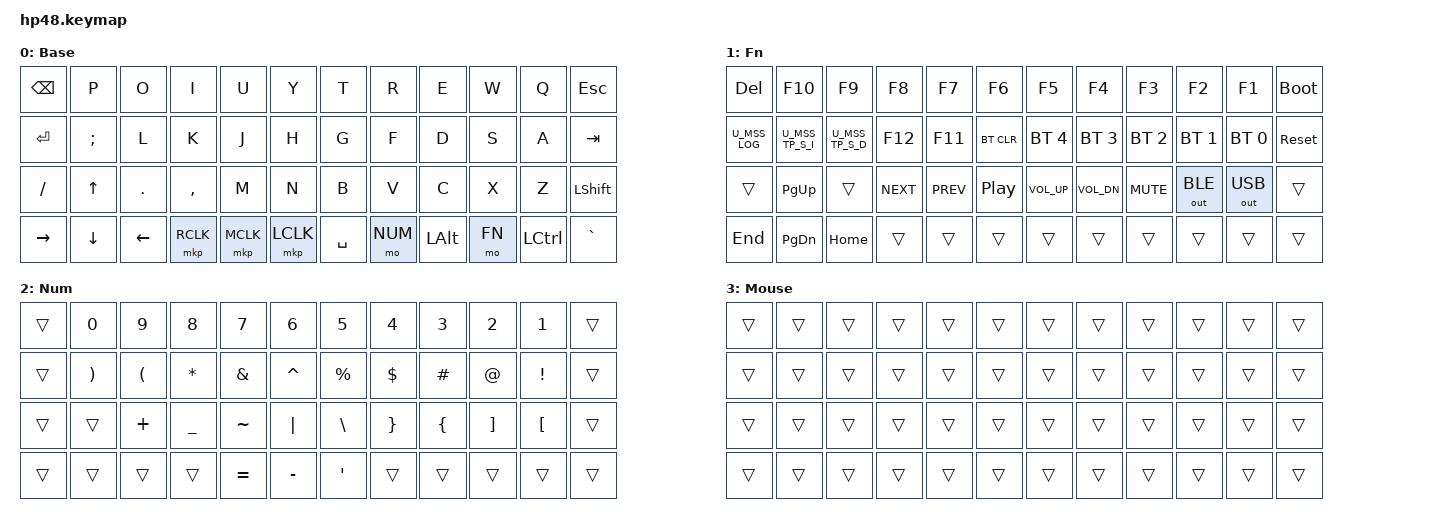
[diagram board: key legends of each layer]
#include <behaviors.dtsi>
#include <dt-bindings/zmk/keys.h>
#include <dt-bindings/zmk/bt.h>
#include <dt-bindings/zmk/outputs.h>

/*
 * Each layer is 48 bindings in physical order: 4 rows of 12 keys.
 * The matrix transform in hp48.overlay (8 rows x 6 columns) maps them:
 *   left half  (keys 1-6 of each row)  -> matrix rows 0-3
 *   right half (keys 7-12 of each row) -> matrix rows 4-7
 *
 * NOTE: every row below is written MIRRORED left-to-right, to match the
 * way this board is wired. Read each row right-to-left to see the layout
 * as it is typed (e.g. the first base-layer row ends with ESC).
 */

#define BASE     0
#define FN       1
#define NUM      2
#define MOUSE_TP 3

// TrackPoint support (mouse_tp.dtsi needs these two defines first)
#define HAS_MOUSE_TP
#include "include/mouse_tp.dtsi"

/ {
    keymap {
        compatible = "zmk,keymap";

        base_layer {
            display-name = "Base";
            bindings = <
&kp BSPC     &kp P        &kp O        &kp I        &kp U        &kp Y        &kp T        &kp R        &kp E        &kp W        &kp Q        &kp ESC
&kp RET      &kp SEMI     &kp L        &kp K        &kp J        &kp H        &kp G        &kp F        &kp D        &kp S        &kp A        &kp TAB
&kp FSLH     &kp UP       &kp DOT      &kp COMMA    &kp M        &kp N        &kp B        &kp V        &kp C        &kp X        &kp Z        &kp LSHFT
&kp RIGHT    &kp DOWN     &kp LEFT     &mkp RCLK    &mkp MCLK    &mkp LCLK    &kp SPACE    &mo NUM      &kp LALT     &mo FN       &kp LCTRL    &kp GRAVE
            >;
        };

        fn_layer {
            display-name = "Fn";
            bindings = <
&kp DEL      &kp F10      &kp F9       &kp F8       &kp F7       &kp F6       &kp F5       &kp F4       &kp F3       &kp F2       &kp F1       &bootloader
U_MSS_LOG    U_MSS_TP_S_I U_MSS_TP_S_D &kp F12      &kp F11      &bt BT_CLR   &bt BT_SEL 4 &bt BT_SEL 3 &bt BT_SEL 2 &bt BT_SEL 1 &bt BT_SEL 0 &sys_reset
&trans       &kp PG_UP    &trans       &kp C_NEXT   &kp C_PREV   &kp C_PP     &kp C_VOL_UP &kp C_VOL_DN &kp C_MUTE   &out OUT_BLE &out OUT_USB &trans
&kp END      &kp PG_DN    &kp HOME     &trans       &trans       &trans       &trans       &trans       &trans       &trans       &trans       &trans
            >;
        };

        num_layer {
            display-name = "Num";
            bindings = <
&trans       &kp N0       &kp N9       &kp N8       &kp N7       &kp N6       &kp N5       &kp N4       &kp N3       &kp N2       &kp N1       &trans
&trans       &kp RPAR     &kp LPAR     &kp ASTRK    &kp AMPS     &kp CARET    &kp PRCNT    &kp DLLR     &kp HASH     &kp AT       &kp EXCL     &trans
&trans       &trans       &kp PLUS     &kp UNDER    &kp TILDE    &kp PIPE     &kp BSLH     &kp RBRC     &kp LBRC     &kp RBKT     &kp LBKT     &trans
&trans       &trans       &trans       &trans       &kp EQUAL    &kp MINUS    &kp SQT      &trans       &trans       &trans       &trans       &trans
            >;
        };

        // Turns on automatically while the TrackPoint is moving.
        // Everything passes through, so the base layer keeps working.
        mouse_tp_layer {
            display-name = "Mouse";
            bindings = <
&trans       &trans       &trans       &trans       &trans       &trans       &trans       &trans       &trans       &trans       &trans       &trans
&trans       &trans       &trans       &trans       &trans       &trans       &trans       &trans       &trans       &trans       &trans       &trans
&trans       &trans       &trans       &trans       &trans       &trans       &trans       &trans       &trans       &trans       &trans       &trans
&trans       &trans       &trans       &trans       &trans       &trans       &trans       &trans       &trans       &trans       &trans       &trans
            >;
        };
    };
};
